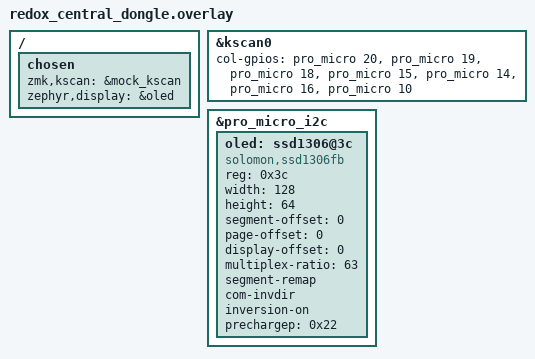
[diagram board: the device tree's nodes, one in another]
#include "redox.dtsi"

/ {
    chosen {
        zmk,kscan = &mock_kscan;
        zephyr,display = &oled;
    };
};

&kscan0 {
    col-gpios
        = <&pro_micro 20 GPIO_ACTIVE_HIGH>
        , <&pro_micro 19 GPIO_ACTIVE_HIGH>
        , <&pro_micro 18 GPIO_ACTIVE_HIGH>
        , <&pro_micro 15 GPIO_ACTIVE_HIGH>
        , <&pro_micro 14 GPIO_ACTIVE_HIGH>
        , <&pro_micro 16 GPIO_ACTIVE_HIGH>
        , <&pro_micro 10 GPIO_ACTIVE_HIGH>
        ;
};

&pro_micro_i2c {
    status = "okay";
    
    oled: ssd1306@3c {
        compatible = "solomon,ssd1306fb";
        reg = <0x3c>;
        width = <128>;
        height = <64>;
        segment-offset = <0>;
        page-offset = <0>;
        display-offset = <0>;
        multiplex-ratio = <63>;
        segment-remap;
        com-invdir;
        inversion-on;
        prechargep = <0x22>;
    };
}; 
